# STM32WBA62 register map
File version: 1.1
CPU: CM33 r0p1, little endian, MPU, FPU, 4 interrupt priority bits
Registers are 32-bit, read-write, reset 0x0 unless marked. A register's access mark holds for its fields unless they carry their own. Offsets are from the block's base; [hi:lo] are bit positions.

## IWDG — IWDG address block description
Base 0x40003000
Same registers: SEC_IWDG 0x50003000
0x00 IWDG_KR wo — IWDG key register
  [15:0] KEY — Key value (write only, read 0x0000)
0x04 IWDG_PR — IWDG prescaler register
  [3:0] PR — Prescaler divider
    0=divider / 4; 1=divider / 8; 2=divider / 16; 3=divider / 32; 4=divider / 64; 5=divider / 128; 6=divider / 256; 7=divider / 512
0x08 IWDG_RLR reset 0xFFF — IWDG reload register
  [11:0] RL — Watchdog counter reload value
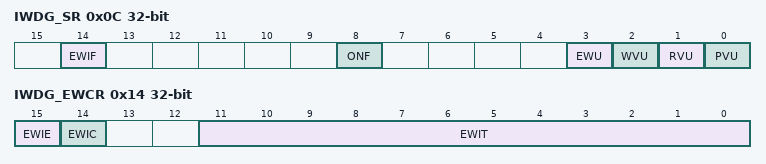
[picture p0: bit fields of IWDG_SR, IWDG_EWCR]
0x0C IWDG_SR ro — IWDG status register
  [14] EWIF — Watchdog early interrupt flag
  [8] ONF — Watchdog enable status bit
    0=The IWDG is not activated; 1=The IWDG is activated and needs to be refreshed regularly by the application
  [3] EWU — Watchdog interrupt comparator value update
  [2] WVU — Watchdog counter window value update
  [1] RVU — Watchdog counter reload value update
  [0] PVU — Watchdog prescaler value update
0x10 IWDG_WINR reset 0xFFF — IWDG window register
  [11:0] WIN — Watchdog counter window value
0x14 IWDG_EWCR — IWDG early wake-up interrupt register
  [15] EWIE — Watchdog early interrupt enable
    0=The early interrupt interface is disabled; 1=The early interrupt interface is enabled
  [14] EWIC wo — Watchdog early interrupt acknowledge
  [11:0] EWIT — Watchdog counter window value

## PTACONV — PTACONV register block
Base 0x48038000
Same registers: SEC_PTACONV 0x58038000
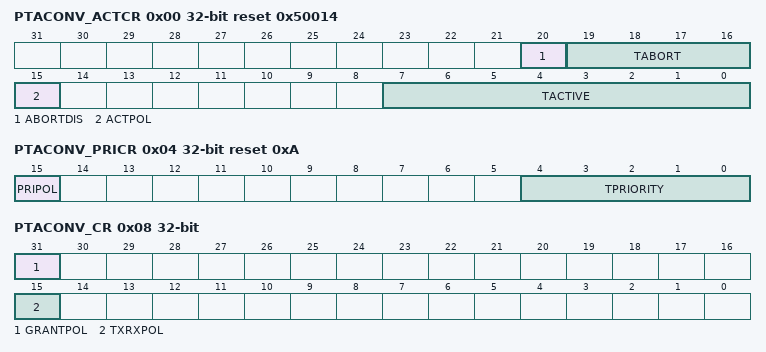
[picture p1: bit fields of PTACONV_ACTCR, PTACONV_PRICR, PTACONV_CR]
0x00 PTACONV_ACTCR reset 0x50014 — PTACONV active control register
  [20] ABORTDIS — Disable PTA_ACTIVE deny to abort an ongoing transmission
    0=PTA_ACTIVE deny will abort an ongoing transmission; 1=PTA_ACTIVE deny will not abort an ongoing transmission
  [19:16] TABORT — PTA_ACTIVE delay to cease an ongoing transmission in us
  [15] ACTPOL — PTA_ACTIVE polarity
    0=PTA_ACTIVE active high; 1=PTA_ACTIVE active low
  [7:0] TACTIVE — PTA_ACTIVE setup time in us
0x04 PTACONV_PRICR reset 0xA — PTACONV priority control register
  [15] PRIPOL — Priority polarity
    0=priority on PTA_PRIORITY or PTA_STATUS not inverted; 1=inverted priority on PTA_PRIORITY or PTA_STATUS
  [4:0] TPRIORITY — Priority valid time in us
    0=no time-multiplexed priority information on PTA_STATUS
0x08 PTACONV_CR — PTACONV control register
  [31] GRANTPOL — PTA_GRANT polarity
    0=PTA_GRANT active low; 1=PTA_GRANT active high
  [15] TXRXPOL — PTA_STATUS transmit and receive polarity
    0=PTA_STATUS receive = 0, transmit = 1; 1=PTA_STATUS receive = 1, transmit = 0

## PKA — PKA register blank and RAM
Base 0x420C2000
Same registers: SEC_PKA 0x520C2000
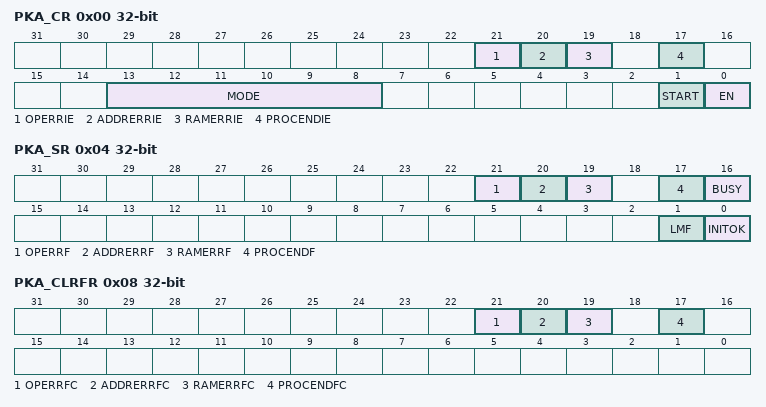
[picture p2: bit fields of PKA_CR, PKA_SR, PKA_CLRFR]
0x00 PKA_CR — PKA control register
  [21] OPERRIE — Operation error interrupt enable
    0=No interrupt is generated when OPERRF flag is set in PKA_SR; 1=An interrupt is generated when OPERRF flag is set in PKA_SR
  [20] ADDRERRIE — Address error interrupt enable
    0=No interrupt is generated when ADDRERRF flag is set in PKA_SR; 1=An interrupt is generated when ADDRERRF flag is set in PKA_SR
  [19] RAMERRIE — RAM error interrupt enable
    0=No interrupt is generated when RAMERRF flag is set in PKA_SR; 1=An interrupt is generated when RAMERRF flag is set in PKA_SR
  [17] PROCENDIE — End of operation interrupt enable
    0=No interrupt is generated when PROCENDF flag is set in PKA_SR; 1=An interrupt is generated when PROCENDF flag is set in PKA_SR
  [13:8] MODE — PKA operation code
    0=Montgomery parameter computation then modular exponentiation; 1=Montgomery parameter computation only; 2=Modular exponentiation only (Montgomery parameter must be loaded first); 3=Modular exponentiation (protected, used when manipulating secrets); 32=Montgomery parameter computation then ECC scalar multiplication (protected); 36=ECDSA sign (protected); 38=ECDSA verification; 40=Point on elliptic curve Fp check; 7=RSA CRT exponentiation; 8=Modular inversion; 9=Arithmetic addition; 10=Arithmetic subtraction; 11=Arithmetic multiplication; 12=Arithmetic comparison; 13=Modular reduction; 14=Modular addition; 15=Modular subtraction; 16=Montgomery multiplication; 35=ECC complete addition; 39=ECC double base ladder; 47=ECC projective to affine
  [1] START — start the operation
  [0] EN — PKA enable
    0=Disable PKA; 1=Enable PKA
0x04 PKA_SR ro — PKA status register
  [21] OPERRF — Operation error flag
    0=No event error; 1=An illegal or unknown operation has been selected in PKA_CR register
  [20] ADDRERRF — Address error flag
    0=No address error; 1=Address access is out of range (unmapped address)
  [19] RAMERRF — PKA RAM error flag
    0=No PKA RAM access error; 1=An AHB access to the PKA RAM occurred while the PKA core was computing and using its internal RAM (AHB PKA_RAM access are not allowed while PKA operation is in progress)
  [17] PROCENDF — PKA end of operation flag
    0=Operation in progress; 1=PKA operation is completed
  [16] BUSY — Busy flag
    0=No operation is in progress (default); 1=An operation is in progress
  [1] LMF — Limited mode flag
    0=All values documented in MODE bit field can be used; 1=Only ECDSA verification (MODE = 0x26) is supported by the PKA
  [0] INITOK — PKA initialization OK
    0=PKA is not initialized correctly; 1=PKA is initialized correctly and can be used normally
0x08 PKA_CLRFR wo — PKA clear flag register
  [21] OPERRFC — Clear operation error flag
    0=No action; 1=Clear the OPERRF flag in PKA_SR
  [20] ADDRERRFC — Clear address error flag
    0=No action; 1=Clear the ADDRERRF flag in PKA_SR
  [19] RAMERRFC — Clear PKA RAM error flag
    0=No action; 1=Clear the RAMERRF flag in PKA_SR
  [17] PROCENDFC — Clear PKA end of operation flag
    0=No action; 1=Clear the PROCENDF flag in PKA_SR
